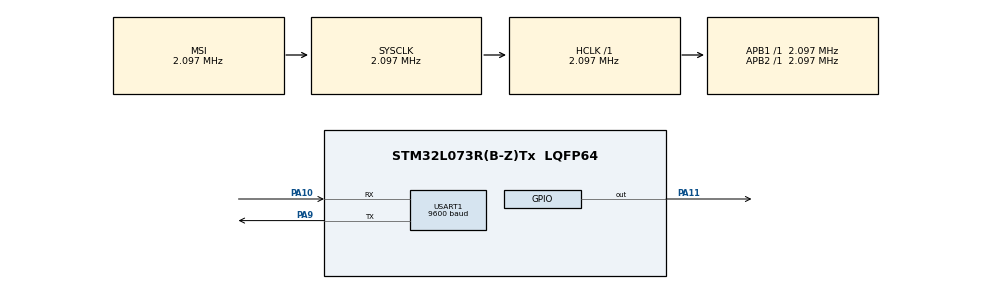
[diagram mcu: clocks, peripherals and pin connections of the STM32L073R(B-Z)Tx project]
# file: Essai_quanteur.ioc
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Mcu.Family=STM32L0
Mcu.Name=STM32L073R(B-Z)Tx
Mcu.Package=LQFP64
NVIC.USART1_IRQn=true\:0\:0\:false\:false\:true\:true\:true\:true
PA10.Mode=Asynchronous
PA10.Signal=USART1_RX
PA11.Signal=GPIO_Output
PA13.Mode=Serial_Wire
PA13.Signal=SYS_SWDIO
PA14.Mode=Serial_Wire
PA14.Signal=SYS_SWCLK
PA9.Mode=Asynchronous
PA9.Signal=USART1_TX
ProjectManager.HeapSize=0x200
ProjectManager.StackSize=0x400
ProjectManager.TargetToolchain=MDK-ARM V5.32
RCC.AHBFreq_Value=2097000
RCC.APB1Freq_Value=2097000
RCC.APB1TimFreq_Value=2097000
RCC.APB2Freq_Value=2097000
RCC.APB2TimFreq_Value=2097000
RCC.HSE_VALUE=8000000
RCC.HSI16_VALUE=16000000
RCC.HSI48_VALUE=48000000
RCC.HSI_VALUE=16000000
RCC.MSI_VALUE=2097000
RCC.SYSCLKFreq_VALUE=2097000
RCC.VCOOutputFreq_Value=48000000
USART1.BaudRate=9600
USART1.VirtualMode-Asynchronous=VM_ASYNC
board=NUCLEO-L073RZ

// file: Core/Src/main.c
/* USER CODE BEGIN Header */
/**
  ******************************************************************************
  * @file           : main.c
  * @brief          : Main program body
  ******************************************************************************
  * @attention
  *
  * Copyright (c) 2023 STMicroelectronics.
  * All rights reserved.
  *
  * This software is licensed under terms that can be found in the LICENSE file
  * in the root directory of this software component.
  * If no LICENSE file comes with this software, it is provided AS-IS.
  *
  ******************************************************************************
  */
/* USER CODE END Header */
#include "main.h"
#include "stm32l0xx_hal.h"
#include "modbus_master.h"

UART_HandleTypeDef huart2;
uint8_t myRxData[7];
HAL_StatusTypeDef uart_rst;
uint8_t result;

void SystemClock_Config(void);
static void MX_GPIO_Init(void);
static void MX_USART1_UART_Init(void);

/* USER CODE BEGIN 0 */
void HAL_UART_RxCpltCallback(UART_HandleTypeDef *huart)
	{
		HAL_UART_Receive_IT(&huart2,myRxData,9);//reset the interruption

	}

/* USER CODE END 0 */

int main(void)
{

  /* MCU Configuration--------------------------------------------------------*/

  /* Reset of all peripherals, Initializes the Flash interface and the Systick. */
  HAL_Init();

  /* Configure the system clock */
  SystemClock_Config();

  /* Initialize all configured peripherals */
  MX_GPIO_Init();
  MX_USART1_UART_Init();
	ModbusMaster_begin();
	HAL_UART_Receive_IT(&huart2,myRxData,7);

  /* Infinite loop */
  while (1)
  {
    HAL_GPIO_WritePin(GPIOA,GPIO_PIN_11,GPIO_PIN_SET);
		result=ModbusMaster_readHoldingRegisters(0x01,1837,1);
		HAL_Delay(2000);
		result=ModbusMaster_readHoldingRegisters(0x01,1838,1);
		HAL_Delay(2000);
		result=ModbusMaster_readHoldingRegisters(0x01,1836,1);

  }
}

void SystemClock_Config(void)
{
  RCC_OscInitTypeDef RCC_OscInitStruct = {0};
  RCC_ClkInitTypeDef RCC_ClkInitStruct = {0};
  RCC_PeriphCLKInitTypeDef PeriphClkInit = {0};

  /** Configure the main internal regulator output voltage
  */
  __HAL_PWR_VOLTAGESCALING_CONFIG(PWR_REGULATOR_VOLTAGE_SCALE1);

  /** Initializes the RCC Oscillators according to the specified parameters
  * in the RCC_OscInitTypeDef structure.
  */
  RCC_OscInitStruct.OscillatorType = RCC_OSCILLATORTYPE_MSI;
  RCC_OscInitStruct.MSIState = RCC_MSI_ON;
  RCC_OscInitStruct.MSICalibrationValue = 0;
  RCC_OscInitStruct.MSIClockRange = RCC_MSIRANGE_5;
  RCC_OscInitStruct.PLL.PLLState = RCC_PLL_NONE;
  if (HAL_RCC_OscConfig(&RCC_OscInitStruct) != HAL_OK)
  {
    Error_Handler();
  }

  /** Initializes the CPU, AHB and APB buses clocks
  */
  RCC_ClkInitStruct.ClockType = RCC_CLOCKTYPE_HCLK|RCC_CLOCKTYPE_SYSCLK
                              |RCC_CLOCKTYPE_PCLK1|RCC_CLOCKTYPE_PCLK2;
  RCC_ClkInitStruct.SYSCLKSource = RCC_SYSCLKSOURCE_MSI;
  RCC_ClkInitStruct.AHBCLKDivider = RCC_SYSCLK_DIV1;
  RCC_ClkInitStruct.APB1CLKDivider = RCC_HCLK_DIV1;
  RCC_ClkInitStruct.APB2CLKDivider = RCC_HCLK_DIV1;

  if (HAL_RCC_ClockConfig(&RCC_ClkInitStruct, FLASH_LATENCY_0) != HAL_OK)
  {
    Error_Handler();
  }
  PeriphClkInit.PeriphClockSelection = RCC_PERIPHCLK_USART1;
  PeriphClkInit.Usart1ClockSelection = RCC_USART1CLKSOURCE_PCLK2;
  if (HAL_RCCEx_PeriphCLKConfig(&PeriphClkInit) != HAL_OK)
  {
    Error_Handler();
  }
}

static void MX_USART1_UART_Init(void)
{

  huart2.Instance = USART1;
  huart2.Init.BaudRate = 9600;
  huart2.Init.WordLength = UART_WORDLENGTH_8B;
  huart2.Init.StopBits = UART_STOPBITS_1;
  huart2.Init.Parity = UART_PARITY_NONE;
  huart2.Init.Mode = UART_MODE_TX_RX;
  huart2.Init.HwFlowCtl = UART_HWCONTROL_NONE;
  huart2.Init.OverSampling = UART_OVERSAMPLING_16;
  huart2.Init.OneBitSampling = UART_ONE_BIT_SAMPLE_DISABLE;
  huart2.AdvancedInit.AdvFeatureInit = UART_ADVFEATURE_NO_INIT;
  if (HAL_UART_Init(&huart2) != HAL_OK)
  {
    Error_Handler();
  }
  /* USER CODE BEGIN USART1_Init 2 */
//	__HAL_UART_ENABLE_IT(&huart2,UART_IT_RXNE);
  /* USER CODE END USART1_Init 2 */

}

static void MX_GPIO_Init(void)
{
  GPIO_InitTypeDef GPIO_InitStruct = {0};

  /* GPIO Ports Clock Enable */
  __HAL_RCC_GPIOA_CLK_ENABLE();

  /*Configure GPIO pin Output Level */
  HAL_GPIO_WritePin(GPIOA, GPIO_PIN_11, GPIO_PIN_RESET);

  /*Configure GPIO pin : PA11 */
  GPIO_InitStruct.Pin = GPIO_PIN_11;
  GPIO_InitStruct.Mode = GPIO_MODE_OUTPUT_PP;
  GPIO_InitStruct.Pull = GPIO_NOPULL;
  GPIO_InitStruct.Speed = GPIO_SPEED_FREQ_LOW;
  HAL_GPIO_Init(GPIOA, &GPIO_InitStruct);

}

void Error_Handler(void)
{
  __disable_irq();
  while (1)
  {
  }
}
